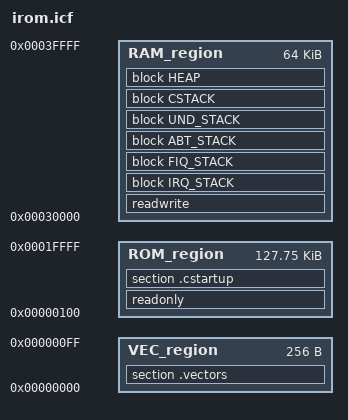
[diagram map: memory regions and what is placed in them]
/*###ICF### Section handled by ICF editor, don't touch! ****/
/*-Editor annotation file-*/
/* IcfEditorFile="$TOOLKIT_DIR$\config\ide\IcfEditor\a_v1_0.xml" */
/*-Memory Regions-*/
define symbol __ICFEDIT_region_ROM_start__ = 0x00000;
define symbol __ICFEDIT_region_ROM_end__   = 0x1FFFF;
define symbol __ICFEDIT_region_RAM_start__ = 0x30000;
define symbol __ICFEDIT_region_RAM_end__   = 0x3ffff;
/*-Sizes-*/
define symbol __ICFEDIT_size_vectors__  = 0x100;
define symbol __ICFEDIT_size_cstack__   = 0x8000;   
define symbol __ICFEDIT_size_irqstack__ = 0x60;
define symbol __ICFEDIT_size_fiqstack__ = 0x60;
define symbol __ICFEDIT_size_abtstack__ = 0x80;
define symbol __ICFEDIT_size_undstack__ = 0x80;

define symbol __ICFEDIT_size_heap__ = 0x400;
/*-Exports-*/
export symbol __ICFEDIT_region_ROM_start__;
export symbol __ICFEDIT_region_ROM_end__;
export symbol __ICFEDIT_region_RAM_start__;
export symbol __ICFEDIT_region_RAM_end__;
export symbol __ICFEDIT_size_vectors__;
export symbol __ICFEDIT_size_cstack__;
export symbol __ICFEDIT_size_irqstack__;
export symbol __ICFEDIT_size_fiqstack__;

export symbol __ICFEDIT_size_heap__;
/**** End of ICF editor section. ###ICF###*/

define memory mem with size = 256K;
define region VEC_region = mem:[from __ICFEDIT_region_ROM_start__ size __ICFEDIT_size_vectors__];
define region RAM_region = mem:[from __ICFEDIT_region_RAM_start__ to __ICFEDIT_region_RAM_end__];
define region ROM_region = mem:[from __ICFEDIT_region_ROM_start__+__ICFEDIT_size_vectors__ to __ICFEDIT_region_ROM_end__];

define block CSTACK    with alignment = 8, size = __ICFEDIT_size_cstack__   { };
define block IRQ_STACK with alignment = 8, size = __ICFEDIT_size_irqstack__ { };
define block FIQ_STACK with alignment = 8, size = __ICFEDIT_size_fiqstack__ { };
define block ABT_STACK with alignment = 8, size = __ICFEDIT_size_abtstack__ { };
define block UND_STACK with alignment = 8, size = __ICFEDIT_size_undstack__ { };
define block HEAP      with alignment = 8, size = __ICFEDIT_size_heap__     { };

initialize by copy with packing=none { readwrite };  
do not initialize  { readonly section .noinit };

place in VEC_region { section .vectors };
place in ROM_region { readonly };
place in ROM_region { section .cstartup };
place in RAM_region { readwrite, block IRQ_STACK, block FIQ_STACK, block ABT_STACK, block UND_STACK, block CSTACK, block HEAP };
